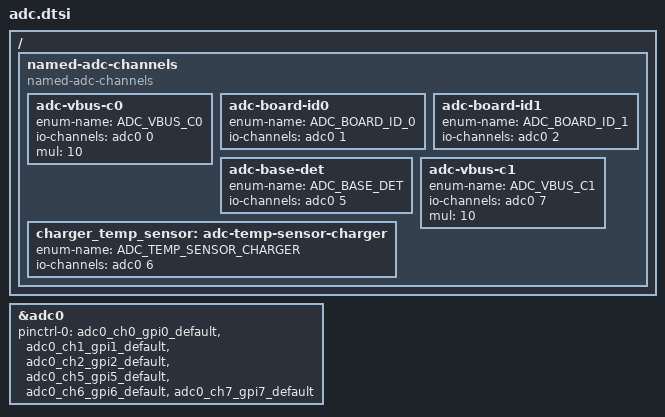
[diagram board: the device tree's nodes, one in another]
/* Copyright 2022 The ChromiumOS Authors
 * Use of this source code is governed by a BSD-style license that can be
 * found in the LICENSE file.
 */

/ {
	named-adc-channels {
		compatible = "named-adc-channels";
		adc-vbus-c0 {
			enum-name = "ADC_VBUS_C0";
			io-channels = <&adc0 0>;
			mul = <10>;
		};
		adc-board-id0 {
			enum-name = "ADC_BOARD_ID_0";
			io-channels = <&adc0 1>;
		};
		adc-board-id1 {
			enum-name = "ADC_BOARD_ID_1";
			io-channels = <&adc0 2>;
		};
		adc-base-det {
			enum-name = "ADC_BASE_DET";
			io-channels = <&adc0 5>;
		};
		charger_temp_sensor: adc-temp-sensor-charger {
			enum-name = "ADC_TEMP_SENSOR_CHARGER";
			io-channels = <&adc0 6>;
		};
		adc-vbus-c1 {
			enum-name = "ADC_VBUS_C1";
			io-channels = <&adc0 7>;
			mul = <10>;
		};
	};
};

&adc0 {
	status = "okay";
	pinctrl-0 = <&adc0_ch0_gpi0_default
		     &adc0_ch1_gpi1_default
		     &adc0_ch2_gpi2_default
		     &adc0_ch5_gpi5_default
		     &adc0_ch6_gpi6_default
		     &adc0_ch7_gpi7_default>;
	pinctrl-names = "default";
};
